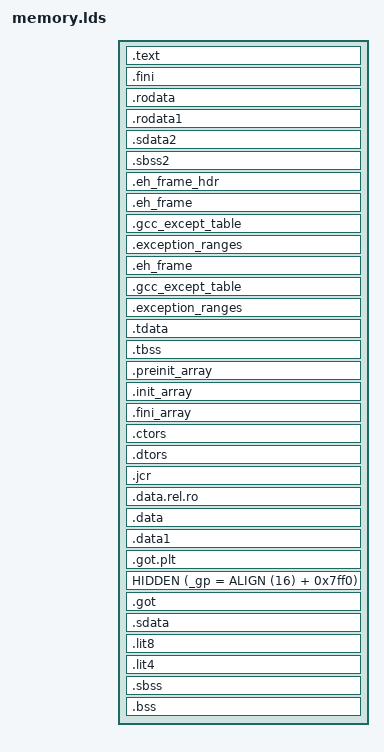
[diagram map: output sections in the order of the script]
OUTPUT_FORMAT("elf32-bigmips", "elf32-bigmips",
              "elf32-littlemips")
OUTPUT_ARCH(mips)

SECTIONS
{
  /* Read-only sections, merged into text segment: */
  PROVIDE (__executable_start = SEGMENT_START("text-segment", 0x0000000)); 
  . = SEGMENT_START("text-segment", 0x0000000);
  .text           :
  {
    _ftext = . ;
    *(.text.startup .text.startup.*)
    *(.text.unlikely .text.*_unlikely .text.unlikely.*)
    *(.text.exit .text.exit.*)
    *(.text.hot .text.hot.*)
    *(.text .stub .text.* .gnu.linkonce.t.*)
    /* .gnu.warning sections are handled specially by elf32.em.  */
    *(.gnu.warning)
    *(.mips16.fn.*) *(.mips16.call.*)
  }
  .fini           :
  {
    KEEP (*(SORT_NONE(.fini)))
  }
  PROVIDE (__etext = .);
  PROVIDE (_etext = .);
  PROVIDE (etext = .);
  .rodata         : { *(.rodata .rodata.* .gnu.linkonce.r.*) }
  .rodata1        : { *(.rodata1) }
  .sdata2         :
  {
    *(.sdata2 .sdata2.* .gnu.linkonce.s2.*)
  }
  .sbss2          : { *(.sbss2 .sbss2.* .gnu.linkonce.sb2.*) }
  .eh_frame_hdr : { *(.eh_frame_hdr) }
  .eh_frame       : ONLY_IF_RO { KEEP (*(.eh_frame)) }
  .gcc_except_table   : ONLY_IF_RO { *(.gcc_except_table
  .gcc_except_table.*) }
  /* These sections are generated by the Sun/Oracle C++ compiler.  */
  .exception_ranges   : ONLY_IF_RO { *(.exception_ranges
  .exception_ranges*) }
  /* Adjust the address for the data segment.  We want to adjust up to
     the same address within the page on the next page up.  */
  . = .;
  /* Exception handling  */
  .eh_frame       : ONLY_IF_RW { KEEP (*(.eh_frame)) }
  .gcc_except_table   : ONLY_IF_RW { *(.gcc_except_table .gcc_except_table.*) }
  .exception_ranges   : ONLY_IF_RW { *(.exception_ranges .exception_ranges*) }
  /* Thread Local Storage sections  */
  .tdata          : { *(.tdata .tdata.* .gnu.linkonce.td.*) }
  .tbss           : { *(.tbss .tbss.* .gnu.linkonce.tb.*) *(.tcommon) }
  .preinit_array     :
  {
    PROVIDE_HIDDEN (__preinit_array_start = .);
    KEEP (*(.preinit_array))
    PROVIDE_HIDDEN (__preinit_array_end = .);
  }
  .init_array     :
  {
    PROVIDE_HIDDEN (__init_array_start = .);
    KEEP (*(SORT(.init_array.*)))
    KEEP (*(.init_array ))
    PROVIDE_HIDDEN (__init_array_end = .);
  }
  .fini_array     :
  {
    PROVIDE_HIDDEN (__fini_array_start = .);
    KEEP (*(SORT(.fini_array.*)))
    KEEP (*(.fini_array ))
    PROVIDE_HIDDEN (__fini_array_end = .);
  }
  .ctors          :
  {
    /* gcc uses crtbegin.o to find the start of
       the constructors, so we make sure it is
       first.  Because this is a wildcard, it
       doesn't matter if the user does not
       actually link against crtbegin.o; the
       linker won't look for a file to match a
       wildcard.  The wildcard also means that it
       doesn't matter which directory crtbegin.o
       is in.  */
    KEEP (*crtbegin.o(.ctors))
    KEEP (*crtbegin?.o(.ctors))
    /* We don't want to include the .ctor section from
       the crtend.o file until after the sorted ctors.
       The .ctor section from the crtend file contains the
       end of ctors marker and it must be last */
    KEEP (*(EXCLUDE_FILE (*crtend.o *crtend?.o ) .ctors))
    KEEP (*(SORT(.ctors.*)))
    KEEP (*(.ctors))
  }
  .dtors          :
  {
    KEEP (*crtbegin.o(.dtors))
    KEEP (*crtbegin?.o(.dtors))
    KEEP (*(EXCLUDE_FILE (*crtend.o *crtend?.o ) .dtors))
    KEEP (*(SORT(.dtors.*)))
    KEEP (*(.dtors))
  }
  .jcr            : { KEEP (*(.jcr)) }
  .data.rel.ro : { *(.data.rel.ro.local* .gnu.linkonce.d.rel.ro.local.*) *(.data.rel.ro .data.rel.ro.* .gnu.linkonce.d.rel.ro.*) }
  .data           :
  {
    _fdata = . ;
    *(.data .data.* .gnu.linkonce.d.*)
    SORT(CONSTRUCTORS)
  }
  .data1          : { *(.data1) }
  .got.plt        : { *(.got.plt) }
  . = .;
  . = .;
  HIDDEN (_gp = ALIGN (16) + 0x7ff0);
  .got            : { *(.got) }
  /* We want the small data sections together, so single-instruction offsets
     can access them all, and initialized data all before uninitialized, so
     we can shorten the on-disk segment size.  */
  .sdata          :
  {
    *(.sdata .sdata.* .gnu.linkonce.s.*)
  }
  .lit8           : { *(.lit8) }
  .lit4           : { *(.lit4) }
  _edata = .; PROVIDE (edata = .);
  . = .;
  __bss_start = .;
  _fbss = .;
  .sbss           :
  {
    *(.dynsbss)
    *(.sbss .sbss.* .gnu.linkonce.sb.*)
    *(.scommon)
  }
  .bss            :
  {
   *(.dynbss)
   *(.bss .bss.* .gnu.linkonce.b.*)
   *(COMMON)
   /* Align here to ensure that the .bss section occupies space up to
      _end.  Align after .bss to ensure correct alignment even if the
      .bss section disappears because there are no input sections.
      FIXME: Why do we need it? When there is no .bss section, we don't
      pad the .data section.  */
   . = ALIGN(. != 0 ? 32 / 8 : 1);
  }
  . = ALIGN(32 / 8);
  . = SEGMENT_START("ldata-segment", .);
  . = ALIGN(32 / 8);
  _end = .; PROVIDE (end = .);
}
